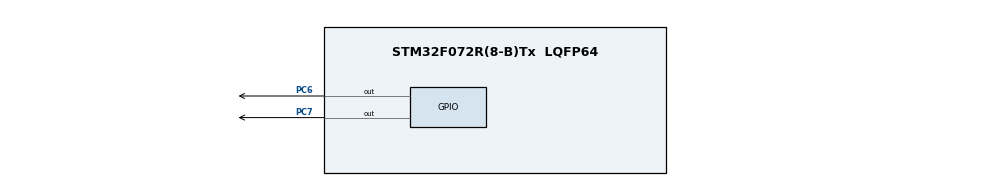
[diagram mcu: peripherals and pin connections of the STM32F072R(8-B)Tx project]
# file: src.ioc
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ADC.ContinuousConvMode=DISABLE
ADC.SamplingTime=ADC_SAMPLETIME_239CYCLES_5
Mcu.Family=STM32F0
Mcu.Name=STM32F072R(8-B)Tx
Mcu.Package=LQFP64
NVIC.ADC1_COMP_IRQn=true\:0\:0\:false\:false\:true\:true\:true
PC6.GPIO_Speed=GPIO_SPEED_FREQ_HIGH
PC6.PinState=GPIO_PIN_RESET
PC6.Signal=GPIO_Output
PC7.GPIO_Speed=GPIO_SPEED_FREQ_HIGH
PC7.PinState=GPIO_PIN_RESET
PC7.Signal=GPIO_Output
ProjectManager.HeapSize=0x200
ProjectManager.StackSize=0x400
ProjectManager.TargetToolchain=EWARM V8.32
VP_ADC_TempSens_Input.Mode=IN-TempSens
board=custom

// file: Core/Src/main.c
/* USER CODE BEGIN Header */
/**
  ******************************************************************************
  * @file           : main.c
  * @brief          : Main program body
  ******************************************************************************
  * @attention
  *
  * <h2><center>&copy; Copyright (c) 2021 STMicroelectronics.
  * All rights reserved.</center></h2>
  *
  * This software component is licensed by ST under BSD 3-Clause license,
  * the "License"; You may not use this file except in compliance with the
  * License. You may obtain a copy of the License at:
  *                        opensource.org/licenses/BSD-3-Clause
  *
  ******************************************************************************
  */
/* USER CODE END Header */
#include "main.h"

/* USER CODE BEGIN Includes */
#include "stdio.h"
#include "math.h"
/* USER CODE END Includes */

/* USER CODE BEGIN PD */
#define size_T 20 // rozmiar tablicy na odczytu z sensora
/* USER CODE END PD */

ADC_HandleTypeDef hadc;

/* USER CODE BEGIN PV */
int ADC_raw = 0; // zmienna na ostatni odczyt z sensora
int ADC_last = 0; // zmienna na przedostatni odczyt z sensora
int difference = 3; // dokladnosc pomiaru, zalozony blad odczytu
int sizeOfTable = size_T; // przypisanie rozmiaru tablicy
int hist_data[size_T]; // definicja bufora cyklicznego na odczyty z sensora
int index = 0; // index bufora
int first_run = 1; // wskaznik pierwszego uruchomienia

uint32_t red_diode = GPIO_PIN_6; /* Przypisanie startowych wartosci dla obu diod */
uint32_t blue_diode = GPIO_PIN_7;

/* USER CODE END PV */

void SystemClock_Config(void);
static void MX_GPIO_Init(void);
static void MX_ADC_Init(void);

/* USER CODE BEGIN 0 */
int max_element(){ // znajdowanie najwiekszego elementu w buforze
  int max = hist_data[0];
  for(int i = 1; i < sizeOfTable; i++){
    if(hist_data[i] > max){
      max = hist_data[i];
    }
  }
  return max;
}

int min_element(){ //znajdowanie najmniejszego elementu w buforze
  int min = hist_data[0];
  for(int i = 1; i < sizeOfTable; i++){
    if(hist_data[i] < min){
      min = hist_data[i];
    }
  }
  return min;
}
// funkcja odpowiadajaca za odczyt z ADC
void HAL_ADC_ConvCpltCallback(ADC_HandleTypeDef* hadc)
{
  if(__HAL_ADC_GET_FLAG(hadc, ADC_FLAG_EOC)){
  // jesli program zostal wlaczony uzupelnij bufor cykliczny aktualnym pomiarem
    if(first_run == 1){
      for(int i = 0; i < sizeOfTable; i++){
        hist_data[i] = HAL_ADC_GetValue(hadc);
      }
      first_run = 0;
    }
    // jesli osiagnieto koniec bufora, zeruj index
    if(index == sizeOfTable){
      index = 0;
    }
    // znajdz najstarszy element w buforze
    int ADC_the_oldest;
    if (index + 1 == sizeOfTable){
      ADC_the_oldest = hist_data[0];
    } else{
      ADC_the_oldest = hist_data[index + 1];
    }
    // poprzedni odczyt
    ADC_last = ADC_raw;
    // odczyt z sensora
    ADC_raw = HAL_ADC_GetValue(hadc);
    hist_data[index] =  ADC_raw;
    // printf("aktualny: %u ", ADC_raw);
    // fflush(stdout);
    int ADC_max = max_element();
    int ADC_min = min_element();
    // Czy roznica miedzy najwiekszym a najmniejszym elementem bufora jest
    // wieksza nic zakladany blad odczytu?
    if(fabs(ADC_max - ADC_min) > difference){
      // czy wartosc rosnie czy maleje?
      if(hist_data[index] - ADC_the_oldest > 0){
        // printf("Maleje\n");
        HAL_GPIO_WritePin(GPIOC, red_diode, GPIO_PIN_RESET); /* zgaszenie diody czerwonej*/
        HAL_GPIO_WritePin(GPIOC, blue_diode, GPIO_PIN_SET); /* zaswiecenie diody niebieskiej*/
      } else{
        // printf("Rosnie\n");
        HAL_GPIO_WritePin(GPIOC, red_diode, GPIO_PIN_SET); /* zaswiecenie diody czerwonej*/
        HAL_GPIO_WritePin(GPIOC, blue_diode, GPIO_PIN_RESET); /* zgaszenie diody niebieskiej*/
      }
      // fflush(stdout);
    }
    index++;
  }
}
/* USER CODE END 0 */

int main(void)
{
  /* USER CODE BEGIN 1 */
  for(int i = 0; i < sizeOfTable; i++){
    hist_data[i] = 0;
  }
  /* USER CODE END 1 */

  /* MCU Configuration--------------------------------------------------------*/

  /* Reset of all peripherals, Initializes the Flash interface and the Systick. */
  HAL_Init();

  /* Configure the system clock */
  SystemClock_Config();

  /* Initialize all configured peripherals */
  MX_GPIO_Init();
  MX_ADC_Init();
  /* USER CODE BEGIN 2 */
  //ADC_Enable(&hadc); // wlaczenie ADC
  HAL_ADC_Start_IT(&hadc); // start AD
  HAL_GPIO_WritePin(GPIOC, red_diode, GPIO_PIN_SET); /* zaswiecenie diody czerwonej*/
  /* USER CODE END 2 */

  /* Infinite loop */
  while (1)
  {

    /* USER CODE BEGIN 3 */
    HAL_Delay(200); // opoznienie 200ms
    HAL_ADC_Start_IT(&hadc); // start AD

  }
  /* USER CODE END 3 */
}

void SystemClock_Config(void)
{
  RCC_OscInitTypeDef RCC_OscInitStruct = {0};
  RCC_ClkInitTypeDef RCC_ClkInitStruct = {0};

  /** Initializes the RCC Oscillators according to the specified parameters
  * in the RCC_OscInitTypeDef structure.
  */
  RCC_OscInitStruct.OscillatorType = RCC_OSCILLATORTYPE_HSI|RCC_OSCILLATORTYPE_HSI14;
  RCC_OscInitStruct.HSIState = RCC_HSI_ON;
  RCC_OscInitStruct.HSI14State = RCC_HSI14_ON;
  RCC_OscInitStruct.HSICalibrationValue = RCC_HSICALIBRATION_DEFAULT;
  RCC_OscInitStruct.HSI14CalibrationValue = 16;
  RCC_OscInitStruct.PLL.PLLState = RCC_PLL_NONE;
  if (HAL_RCC_OscConfig(&RCC_OscInitStruct) != HAL_OK)
  {
    Error_Handler();
  }
  /** Initializes the CPU, AHB and APB buses clocks
  */
  RCC_ClkInitStruct.ClockType = RCC_CLOCKTYPE_HCLK|RCC_CLOCKTYPE_SYSCLK
                              |RCC_CLOCKTYPE_PCLK1;
  RCC_ClkInitStruct.SYSCLKSource = RCC_SYSCLKSOURCE_HSI;
  RCC_ClkInitStruct.AHBCLKDivider = RCC_SYSCLK_DIV1;
  RCC_ClkInitStruct.APB1CLKDivider = RCC_HCLK_DIV1;

  if (HAL_RCC_ClockConfig(&RCC_ClkInitStruct, FLASH_LATENCY_0) != HAL_OK)
  {
    Error_Handler();
  }
}

static void MX_ADC_Init(void)
{

  ADC_ChannelConfTypeDef sConfig = {0};

  /** Configure the global features of the ADC (Clock, Resolution, Data Alignment and number of conversion)
  */
  hadc.Instance = ADC1;
  hadc.Init.ClockPrescaler = ADC_CLOCK_ASYNC_DIV1;
  hadc.Init.Resolution = ADC_RESOLUTION_12B;
  hadc.Init.DataAlign = ADC_DATAALIGN_RIGHT;
  hadc.Init.ScanConvMode = ADC_SCAN_DIRECTION_FORWARD;
  hadc.Init.EOCSelection = ADC_EOC_SINGLE_CONV;
  hadc.Init.LowPowerAutoWait = DISABLE;
  hadc.Init.LowPowerAutoPowerOff = DISABLE;
  hadc.Init.ContinuousConvMode = DISABLE;
  hadc.Init.DiscontinuousConvMode = DISABLE;
  hadc.Init.ExternalTrigConv = ADC_SOFTWARE_START;
  hadc.Init.ExternalTrigConvEdge = ADC_EXTERNALTRIGCONVEDGE_NONE;
  hadc.Init.DMAContinuousRequests = DISABLE;
  hadc.Init.Overrun = ADC_OVR_DATA_PRESERVED;
  if (HAL_ADC_Init(&hadc) != HAL_OK)
  {
    Error_Handler();
  }
  /** Configure for the selected ADC regular channel to be converted.
  */
  sConfig.Channel = ADC_CHANNEL_TEMPSENSOR;
  sConfig.Rank = ADC_RANK_CHANNEL_NUMBER;
  sConfig.SamplingTime = ADC_SAMPLETIME_239CYCLES_5;
  if (HAL_ADC_ConfigChannel(&hadc, &sConfig) != HAL_OK)
  {
    Error_Handler();
  }

}

static void MX_GPIO_Init(void)
{
  GPIO_InitTypeDef GPIO_InitStruct = {0};

  /* GPIO Ports Clock Enable */
  __HAL_RCC_GPIOC_CLK_ENABLE();

  /*Configure GPIO pin Output Level */
  HAL_GPIO_WritePin(GPIOC, GPIO_PIN_6|GPIO_PIN_7, GPIO_PIN_RESET);

  // konfiguracja odpowiedzialna za diody
  /*Configure GPIO pins : PC6 PC7 */
  GPIO_InitStruct.Pin = GPIO_PIN_6|GPIO_PIN_7;
  GPIO_InitStruct.Mode = GPIO_MODE_OUTPUT_PP;
  GPIO_InitStruct.Pull = GPIO_NOPULL;
  GPIO_InitStruct.Speed = GPIO_SPEED_FREQ_HIGH;
  HAL_GPIO_Init(GPIOC, &GPIO_InitStruct);

}

void Error_Handler(void)
{
  __disable_irq();
  while (1)
  {
  }
}

/************************ (C) COPYRIGHT STMicroelectronics *****END OF FILE****/
